# XN11EXXX register map
File version: 1.3
CPU: CM0 r0p0, little endian, no MPU, no FPU, 2 interrupt priority bits
Registers are 32-bit, read-write, reset 0x0 unless marked. A register's access mark holds for its fields unless they carry their own. Offsets are from the block's base; lines under a group give offsets from that group; [hi:lo] are bit positions; {n}, {i} and the like mark numbered series; 'fields as' and 'values as' point back to an identical list; <NAME> marks a mode.

## Memory map
0x1FFF1400 DIA size 0x200 — Device information array
0x40000000 TWS size 0x4000 — two wires serial communication interface
0x40004000 WDT size 0x4000 — Watch dog
0x40008000 UART0 size 0x4000 — Universal asynchronous receiver/transmitter
0x4000C000 UART1 size 0x4000
0x40010000 CT16B0 size 0x4000 — 16 bits timer
0x40014000 CT16B1 size 0x4000 — 16 bits timer
0x40018000 CT16B2 size 0x4000 — 16 bits timer
0x4001C000 CT16B3 size 0x4000 — 16 bits timer
0x40020000 ADC size 0x4000 — Analog-to-Digital Converter
0x40038000 PMU size 0x4000 — Power management unit
0x40040000 SPI size 0x4000 — Serial peripheral interface
0x40044000 IOCON size 0x4000 — I/O configuration block
0x40048000 SYSCON size 0x4000 — System control register
0x4004C000 PWM size 0x4000 — Pulse-Width Modulation
0x40050000 RTC size 0x4000 — Real-time clock
0x40068000 LCD size 0x4000 — LCD driver
0x40078000 CAPTOUCH size 0x4000 — Capacitance Touch Sense
0x50000000 GPIO0 size 0x10000 — General-purpose I/Os
0x50010000 GPIO1 size 0x10000
0x50020000 GPIO2 size 0x10000 — General-purpose I/Os
0x50060000 FMC size 0x10000 — Flash control block
0x50070000 CRC size 0x10000 — Micro digital signal processor

## Interrupts
0 WAKEUP (SYSCON) — WAKEUP interrupt
1 PMWFAULT (PWM) — PWM fault interrupt
2 TWS — TWS interrupt
3 CT16B0 — CT16B0 interrupt
4 CT16B1 — CT16B1 interrupt
5 CT16B2 — CT16B2 interrupt
6 CT16B3 — CT16B3 interrupt
7 UART0 — UART0 interrupt
8 UART1 — UART1 interrupt
9 ADC — ADC interrupt
10 WDT — WDT interrupt
11 BOD (SYSCON) — BOD interrupt
12 GPIO0 — GPIO0 interrupt
13 GPIO1 — GPIO1 interrupt
14 GPIO2 — GPIO2 interrupt
15 RTC — RTC interrupt
16 SPI — SPI interrupt
17 PWMEVENT (PWM) — PWM Event interrupt
18 CAPTOUCH — CAP TOUCH interrupt

## DIA — Device information array
Base 0x1FFF1400
0x04 FUNCDESC ro — Device function description
0x08 DID ro — Device ID
0x0C VERID ro — Hardware version
0x10 UNIQUEID0 ro — Unique device serial no- low 32-bit
0x14 UNIQUEID1 ro — Unique device serial no- high 32-bit
0x18 IRCTRIM ro — Internal IRC trim bits

## TWS — two wires serial communication interface
Base 0x40000000
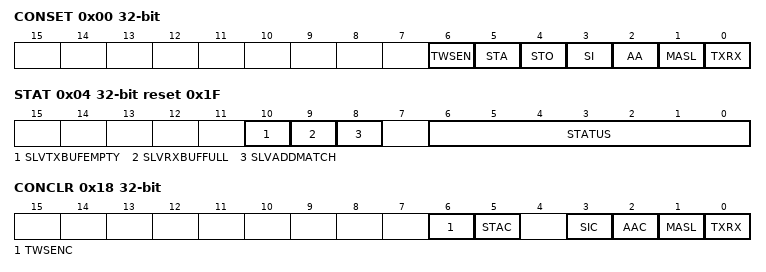
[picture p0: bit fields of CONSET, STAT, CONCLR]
0x00 CONSET — TWS control set bit register
  [6] TWSEN — TWS interface enable
  [5] STA — START flag
  [4] STO — STOP flag
  [3] SI — TWS interrupt flag
  [2] AA — Assert acknowledge flag
  [1] MASL — Master/slave flag
  [0] TXRX — Transmit/receive flag
0x04 STAT ro reset 0x1F — TWS state register
  [10] SLVTXBUFEMPTY — Slave transmitter buffer is empty
  [9] SLVRXBUFFULL — Slave receiver buffer is full
  [8] SLVADDMATCH — Slave address matched
  [6:0] STATUS — These bits give the actual status information about the TWS interface
0x08 DAT — TWS data register
  [7:0] DATA — This register holds data values that have been received or are to be transmitted
0x0C ADR0 — TWS Slave Address Register 0
  [7:1] ADDR — The TWS device address for slave mode
0x10 SCLH reset 0x4 — Duty Cycle Register High Half Word
  [15:0] SCLH — Count for TWS high time period selection
0x14 SCLL reset 0x4 — Duty Cycle Register Low Half Word
  [15:0] SCLL — Count for TWS low time period selection
0x18 CONCLR wo — TWS Control Clear Register
  [6] TWSENC — TWS interface Disable bit
  [5] STAC — START flag Clear bit
  [3] SIC — Interrupt Clear bit
  [2] AAC — Assert acknowledge Clear bit
  [1] MASL — Master/slave select Clear bit
  [0] TXRX — TX/RX select Clear bit
0x20 ADR1 — TWS Slave Address Register 1
  [7:1] ADDR — The TWS device address for slave mode
0x24 ADR2 — TWS slave address register2
  [7:1] ADDR — The TWS device address for slave mode
0x28 ADR3 — TWS slave address register3
  [7:1] ADDR — The TWS device address for slave mode
0x2C DATA_BUFFER ro — TWS data buffer register
  [7:0] DATA — This register holds contents of the 8 MSBs of the DAT shift register
{0x30+4i} MASK{i} (i=0..3) — TWS address mask register{i}
  [7:1] MASK — Mask bits
